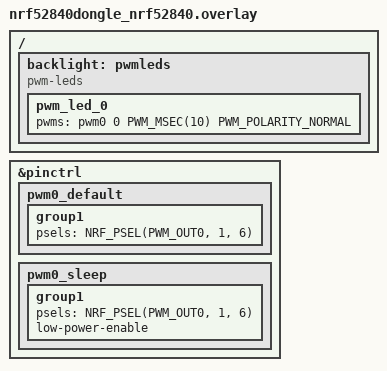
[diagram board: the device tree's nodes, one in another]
/ {
    backlight: pwmleds {
        compatible = "pwm-leds";
        status = "okay";
        pwm_led_0 {
            pwms = <&pwm0 0 PWM_MSEC(10) PWM_POLARITY_NORMAL>;
        };
    };
};

&pinctrl {
    pwm0_default: pwm0_default {
        group1 {
            psels = <NRF_PSEL(PWM_OUT0, 1, 6)>;
        };
    };
    pwm0_sleep: pwm0_sleep {
        group1 {
            psels = <NRF_PSEL(PWM_OUT0, 1, 6)>;
            low-power-enable;
        };
    };
};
